# CY8C5888LTQ_LP097 register map
File version: 0.1
Registers are 8-bit, read-write, no defined reset value unless marked. A register's access mark holds for its fields unless they carry their own. Offsets are from the block's base; [hi:lo] are bit positions; {n}, {i} and the like mark numbered series; 'fields as' and 'values as' point back to an identical list.

## PGA_1
Base 0x00000000
0x400043A9 SC__PM_ACT_CFG — Active Power Mode Configuration Register 9
  [3:0] en_swcap ro — Enable switchcap block(s)
    1=en_swcap_0_ (Enables SC Block 0); 2=en_swcap_1_ (Enables SC Block 1); 4=en_swcap_2_ (Enables SC Block 2); 8=en_swcap_3_ (Enables SC Block 3)
0x400043B9 SC__PM_STBY_CFG — Standby Power Mode Configuration Register 9
  fields as SC__PM_ACT_CFG
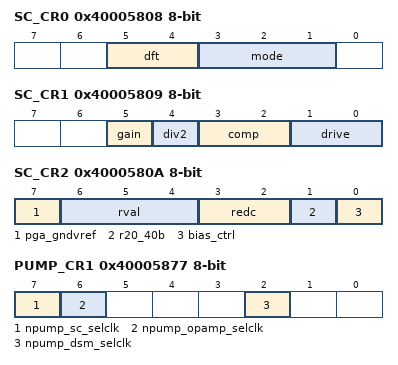
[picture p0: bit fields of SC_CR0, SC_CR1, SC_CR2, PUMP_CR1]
0x40005808 SC_CR0 — Switched Capacitor Control Register 0
  [5:4] dft ro — Configuration select for the SC block
    0=SC_DFT_NORMAL (Normal Operation); 1=SC_DFT_VBOOST (Vboost DFT); 2=SC_DFT_MODE_DEPENDENT (Mode Dependent (PGA Mode = Voltage Integrator, TIA Mode = Charge Integrator, Naked Opamp Mode = Comparator)); 3=SC_DFT_RESET (DFT reset)
  [3:1] mode ro — Configuration select for the SC block
    0=SC_MODE_NAKED_OPAMP (Naked Op-Amp); 1=SC_MODE_TIA (Transimpedance Amplifier); 2=SC_MODE_CTMIXER (Continuous Time Mixer); 3=SC_MODE_NRZ_SH (Discrete Time Mixer - NRZ S/H); 4=SC_MODE_UNITY (Unity Gain Buffer); 5=SC_MODE_1ST_MOD (First Order Modulator); 6=SC_MODE_PGA (Programmable Gain Amplifier (PGA)); 7=SC_MODE_TRACKANDHOLD (Track and Hold)
0x40005809 SC_CR1 — Switched Capacitor Control Register 1
  [5] gain ro — Controls the ratio of the feedback cap for S/H Mixer mode and PGA mode
    0=GAIN_0DB (0 dB); 1=GAIN_6DB (6 dB)
  [4] div2 ro — When 0, the sample clock only needs to be half the desired sample frequency for S/H Mixer mode
    0=SC_DIV2_DISABLEF (no frequency division); 1=SC_DIV2_ENABLE (SC CLK is divided by two)
  [3:2] comp ro — Selects between various compensation capacitor sizes
    0=SC_COMP_3P0PF (3.0pF); 1=SC_COMP_3P6PF (3.6pF); 2=SC_COMP_4P35PF (4.35pF); 3=SC_COMP_5P1PF (5.1pF)
  [1:0] drive ro — Selects between current settings (I_Load (uA)) in the output buffer
    0=I_LOAD_175UA (175 uA); 1=I_LOAD_260UA (260 uA); 2=I_LOAD_330UA (330 uA); 3=I_LOAD_400UA (400 uA)
0x4000580A SC_CR2 — Switched Capacitor Control Register 2
  [7] pga_gndvref ro — Programmable Gain Amplifier Application - Ground VREF)
    0=SC_PGA_GNDVREF_DIS (VREF not grounded); 1=SC_PGA_GNDVREF_EN (VREF grounded)
  [6:4] rval — Programmable Gain Amplifier (PGA) and Transimpedance Amplifier (TIA): Feedback resistor (Rfb)
    0=SC_RVAL_20 (20 kOhm); 1=SC_RVAL_30 (30 kOhm); 2=SC_RVAL_40 (40 kOhm); 3=SC_RVAL_80 (80 kOhm); 4=SC_RVAL_120 (120 kOhm); 5=SC_RVAL_250 (250 kOhm); 6=SC_RVAL_500 (500 kOhm); 7=SC_RVAL_1000 (1 MegaOhm)
  [3:2] redc — Another stability control setting. Adjusts capactiance between amplifier output and first stage
    0=SC_REDC_00 (Varies depending on mode. See Switched Cap documentation); 1=SC_REDC_01 (Varies depending on mode. See Switched Cap documentation); 2=SC_REDC_10 (Varies depending on mode. See Switched Cap documentation); 3=SC_REDC_11 (Varies depending on mode. See Switched Cap documentation)
  [1] r20_40b — PGA Mode: input impedance (Rin), Mixer Mode: input and feedback impedance (Rmix)
    0=SC_R20_40B_40K (40kOhm); 1=SC_R20_40B_20K (20kOhm)
  [0] bias_ctrl ro — Toggles the bias current in the amplifier between normal and 1/2
    0=BIAS_1X (1x current reference reduces bandwidth to increase stability); 1=BIAS_2X (normal operation - 2x current reference to increase bandwidth)
0x40005877 PUMP_CR1 — Pump Configuration Register 1
  [7] npump_sc_selclk ro — Switched Cap Negative Pump Clock Selection
    0=NPUMP_SC_SELCLK_EXTERNAL (External (DSI) clock selected); 1=NPUMP_SC_SELCLK_INTERNAL_ (Negative pump internal clock selected)
  [6] npump_opamp_selclk ro — Opamp Negative Pump Clock Selection
    0=NPUMP_OPAMP_SELCLK_EXTERNAL (External (DSI) clock selected); 1=NPUMP_OPAMP_SELCLK_INTERNAL_ (Negative pump internal clock selected)
  [2] npump_dsm_selclk ro — DSM Negative Pump Clock Selection
    0=NPUMP_DSM_SELCLK_EXTERNAL (External (DSI) clock selected); 1=NPUMP_DSM_SELCLK_INTERNAL (Negative pump internal clock selectedd)
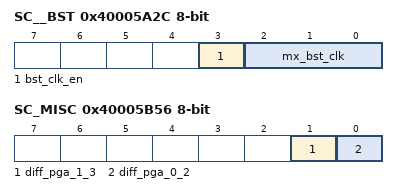
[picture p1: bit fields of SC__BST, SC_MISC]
0x40005A2C SC__BST — Switched Capacitor Boost Clock Selection Register
  [3] bst_clk_en — Clock gating control
    0=CLK_EN_0 (disable clock); 1=CLK_EN_1 (enable clock)
  [2:0] mx_bst_clk — Clock Selection
    {v}=MX_CLK_{v} (Select clk_a{v} and clk_a{v}_dig) (v=0..3); 4=MX_CLK_4 (Select UDB generated clock); 5=MX_CLK_5 (Reserved); 6=MX_CLK_6 (Reserved); 7=MX_CLK_7 (Reserved)
0x40005B56 SC_MISC — Switched Cap Miscellaneous Control Register
  [1] diff_pga_1_3 ro — Switched Cap Pair Connect for Differential Amplifier Applications
    0=SC_DIFF_PGA_DISABLED (Differential PGA pair connect disabled); 1=SC_DIFF_PGA_ENABLED (Differential PGA pair connect enabled)
  [0] diff_pga_0_2 ro — Switched Cap Pair Connect for Differential Amplifier Applications
    0=SC_DIFF_PGA_DISABLED (Differential PGA pair connect disabled); 1=SC_DIFF_PGA_ENABLED_ (Differential PGA pair connect enabled)

## PWM_1
Base 0x00000000
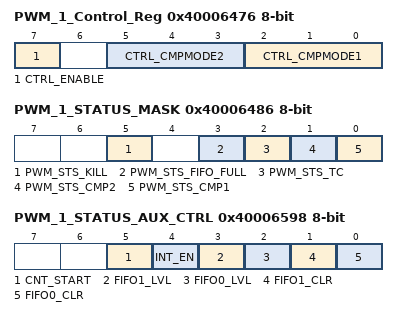
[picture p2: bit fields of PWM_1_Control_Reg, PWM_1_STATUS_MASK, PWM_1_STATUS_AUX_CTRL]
0x40006476 PWM_1_Control_Reg — UDB Control Register - Assigned Control Register Value
  [7] CTRL_ENABLE — Enable the PWM
  [5:3] CTRL_CMPMODE2 — Compare mode 2
  [2:0] CTRL_CMPMODE1 — Compare mode 1
0x40006486 PWM_1_STATUS_MASK — UDB Status bits Interrupt Mask Enable Register
  [5] PWM_STS_KILL ro — Enables the Interrupt on Kill
  [3] PWM_STS_FIFO_FULL ro — FIFO Full Status Mask
  [2] PWM_STS_TC ro — Enables the Interrupt on Terminal Count
  [1] PWM_STS_CMP2 ro — Enables the Interrupt on Compare 2
  [0] PWM_STS_CMP1 ro — Enables the Interrupt on Compare 1
0x40006528 PWM_1__COMPARE1 — UDB.D0 - Assigned Compare1 Value
0x40006538 PWM_1__COMPARE2 — UDB.D1 - Assigned Compare2 Value
0x40006598 PWM_1_STATUS_AUX_CTRL — UDB Auxilliary Control Register
  [5] CNT_START — FIFO0 clear
    0=E_CNT_START0 (Disable counter); 1=E_CNT_START1 (Enable counter)
  [4] INT_EN
    0=E_INT_EN0 (Interrupt disabled); 1=E_INT_EN1 (Interrupt enabled)
  [3] FIFO1_LVL — FIFO level
    0=E_FIFO_LVL_0 (FIFO LVL: input mode: FIFO not full; output mode: FIFO not empty); 1=E_FIFO_LVL_1 (FIFO LVL: input mode: FIFO at least 1/2 empty; output mode: FIFO at least 1/2 full)
  [2] FIFO0_LVL — FIFO level
    values as FIFO1_LVL
  [1] FIFO1_CLR — FIFO1 clear
    0=E_FIFO_CLR_0 (Normal FIFO operation); 1=E_FIFO_CLR_1 (Clear FIFO state)
  [0] FIFO0_CLR — FIFO0 clear
    values as FIFO1_CLR
